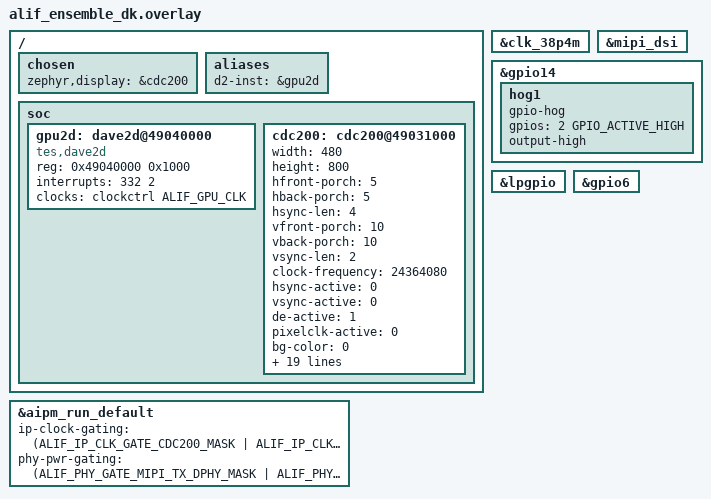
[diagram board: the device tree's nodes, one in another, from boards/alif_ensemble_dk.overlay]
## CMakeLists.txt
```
# Copyright (C) Alif Semiconductor - All Rights Reserved.
# Use, distribution and modification of this code is permitted under the
# terms stated in the Alif Semiconductor Software License Agreement
#
# You should have received a copy of the Alif Semiconductor Software
# License Agreement with this file. If not, please write to:
# contact@alifsemi.com, or visit: https://alifsemi.com/license
#

cmake_minimum_required(VERSION 3.20.0)

find_package(Zephyr REQUIRED HINTS $ENV{ZEPHYR_BASE})
project(lvgl_gui)

# The declarative UI in ui/screen_main.xml is exported to C by
# scripts/gen_ui_xml.py. Generate it into the build tree (never the source
# tree) so read-only-source checkouts and parallel twister builds cannot race
# on a shared file. src/ui_xml.h stays in src/ as the stable interface.
set(ui_xml_c ${CMAKE_CURRENT_BINARY_DIR}/ui_xml.c)

# Application sources: the display bring-up and the exported UI.
target_sources(app PRIVATE
    src/main.c
    ${ui_xml_c}
    src/Alif240_white.c
)

# The generated C includes "ui_xml.h", which lives in src/.
target_include_directories(app PRIVATE src)

# Runs only when the XML or the generator changes.
add_custom_command(
    OUTPUT  ${ui_xml_c}
    COMMAND ${PYTHON_EXECUTABLE}
            ${CMAKE_CURRENT_SOURCE_DIR}/scripts/gen_ui_xml.py
            ${CMAKE_CURRENT_SOURCE_DIR}/ui/screen_main.xml
            ${ui_xml_c}
    DEPENDS ${CMAKE_CURRENT_SOURCE_DIR}/ui/screen_main.xml
            ${CMAKE_CURRENT_SOURCE_DIR}/scripts/gen_ui_xml.py
    COMMENT "Generating ui_xml.c from ui/screen_main.xml"
    VERBATIM
)

# LVGL's upstream D/AVE 2D draw unit includes "bsp_api.h" (LVGL 9.5.0+). The
# include/ directory provides a compatibility shim that maps the TES D/AVE 2D
# driver headers. It must be visible to the LVGL module library build (not just
# the app), so add it to the global include path.
zephyr_include_directories(include)

# The D/AVE 2D draw unit gates its D-cache maintenance (clean/invalidate of the
# GPU source and destination buffers) behind ARM_CORTEX_M55_M85 and
# BSP_CFG_DCACHE_ENABLED. The Alif Cortex-M55 runs with D-cache enabled and the
# GPU buffers live in cacheable SRAM, so this maintenance is required for
# CPU/GPU coherency. Define the macros for the whole build (the LVGL module
# needs them too, not just the app).
zephyr_compile_definitions(ARM_CORTEX_M55_M85=1 BSP_CFG_DCACHE_ENABLED=1)

# The LVGL rendering buffers (.lvgl_buf) and memory pool (.lvgl_heap) are
# rendered into by the D/AVE 2D GPU as a bus master, so relocate them into
# globally addressable SRAM0. In DIRECT mode these full-screen VDBs also serve
# as the CDC200 scan-out framebuffers (zero-copy page-flip).
zephyr_linker_sources_ifdef(CONFIG_LV_Z_VDB_CUSTOM_SECTION
    SECTIONS lvgl_sram.ld)
```

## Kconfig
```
# Copyright (C) Alif Semiconductor - All Rights Reserved.
# Use, distribution and modification of this code is permitted under the
# terms stated in the Alif Semiconductor Software License Agreement
#
# You should have received a copy of the Alif Semiconductor Software
# License Agreement with this file. If not, please write to:
# contact@alifsemi.com, or visit: https://alifsemi.com/license
#

mainmenu "LVGL GUI"

config APP_DAVE2D_HEAP_HWM
	bool "Report the D/AVE 2D heap high-water mark"
	help
	  Fill the D/AVE 2D heap with a known pattern before the heap manager
	  is initialised and periodically log the highest byte that was ever
	  written.

config APP_LVGL_HEAP_STATS
	bool "Report LVGL memory pool and main stack usage"
	select SYS_HEAP_RUNTIME_STATS
	select INIT_STACKS
	select THREAD_STACK_INFO
	help
	  Periodically log the current and peak usage of the LVGL memory pool
	  and the peak usage of the main thread stack.

source "Kconfig.zephyr"
```

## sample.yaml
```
# Copyright (C) Alif Semiconductor - All Rights Reserved.
# Use, distribution and modification of this code is permitted under the
# terms stated in the Alif Semiconductor Software License Agreement
#
# You should have received a copy of the Alif Semiconductor Software
# License Agreement with this file. If not, please write to:
# contact@alifsemi.com, or visit: https://alifsemi.com/license
#

sample:
  name: LVGL XML Widgets
  description: >
    LVGL UI built from a declarative XML description covering the common LVGL
    widgets, exported to C and rendered through the D/AVE 2D GPU on the Alif
    Ensemble E8 DevKit MW405 display.
common:
  modules:
    - lvgl
  tags:
    - display
    - lvgl
    - gui
    - xml
    - dave2d
    - gpu2d
  harness: console
  harness_config:
    type: one_line
    regex:
      - "XML widgets UI created"
  depends_on: display
tests:
  sample.modules.lvgl.gui.dave2d:
    platform_allow:
      - alif_e8_dk/ae822fa0e5597xx0/rtss_he
      - alif_e8_dk/ae822fa0e5597xx0/rtss_hp
    integration_platforms:
      - alif_e8_dk/ae822fa0e5597xx0/rtss_he
```

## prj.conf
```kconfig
# Copyright (C) Alif Semiconductor - All Rights Reserved.
# Use, distribution and modification of this code is permitted under the
# terms stated in the Alif Semiconductor Software License Agreement
#
# You should have received a copy of the Alif Semiconductor Software
# License Agreement with this file. If not, please write to:
# contact@alifsemi.com, or visit: https://alifsemi.com/license
#

# Display pipeline: CDC200 controller + MIPI-DSI host + MW405 panel.
CONFIG_DISPLAY=y
CONFIG_MIPI_DSI=y

# LVGL core.
CONFIG_LVGL=y

# Widgets used by the exported UI (ui/screen_main.xml -> src/ui_xml.c). Most
# default to y in the LVGL Kconfig; set them explicitly so the sample is
# self-contained and does not silently drop a widget if a default changes.
CONFIG_LV_USE_LABEL=y
CONFIG_LV_USE_BUTTON=y
CONFIG_LV_USE_SLIDER=y
CONFIG_LV_USE_BAR=y
CONFIG_LV_USE_SWITCH=y
CONFIG_LV_USE_CHECKBOX=y
CONFIG_LV_USE_ARC=y
CONFIG_LV_USE_LED=y
CONFIG_LV_USE_LINE=y
CONFIG_LV_USE_IMAGE=y

# Fonts used by the UI (montserrat_14 is the default font; 24 is used for the
# title label).
CONFIG_LV_FONT_MONTSERRAT_14=y
CONFIG_LV_FONT_MONTSERRAT_24=y

# Flexbox layout used by the root container in the exported UI.
CONFIG_LV_USE_FLEX=y

# Refresh at ~60 FPS (LVGL default is 33 ms / ~30 FPS).
CONFIG_LV_DEF_REFR_PERIOD=16

# LVGL memory pool. Every lv_malloc() comes from here: widget objects, the
# simple-layer scratch buffers and the transient glyph bitmaps lv_draw_label
# allocates per letter. The UI peaks at about 11 KB; 64 KB leaves room for
# UI changes. It lives in .lvgl_heap (SRAM0). The pool is a sys_heap that
# defaults to SYS_HEAP_SMALL_ONLY (DTCM is 256 KB), which supports at most
# 262136 bytes; set CONFIG_SYS_HEAP_AUTO=y if the pool is made larger.
CONFIG_LV_Z_MEM_POOL_SIZE=65536
CONFIG_LV_DRAW_LAYER_SIMPLE_BUF_SIZE=49152

# Double-buffered, statically allocated rendering buffers. The custom sections
# (.lvgl_buf / .lvgl_heap) are relocated to globally-addressable SRAM0 by
# lvgl_sram.ld so the D/AVE 2D GPU can render into them and the VDBs can also
# serve as the CDC200 scan-out framebuffers (DIRECT mode zero-copy page-flip).
CONFIG_LV_Z_BUFFER_ALLOC_STATIC=y
CONFIG_LV_Z_DOUBLE_VDB=y
CONFIG_LV_Z_VDB_CUSTOM_SECTION=y
CONFIG_LV_Z_MEMORY_POOL_CUSTOM_SECTION=y

# Size the VDBs for the RGB565 panel (16 bpp). The Zephyr LVGL Kconfig has an
# unconditional "default 32" before the "default 16 if LV_COLOR_DEPTH_16"
# entry, so pin the bits-per-pixel explicitly.
CONFIG_LV_Z_BITS_PER_PIXEL=16

# DIRECT-mode rendering: two full-screen VDBs in SRAM0 ARE the scan-out
# framebuffers. main.c page-flips via cdc200_swap_fb() at vsync.
CONFIG_LV_Z_VDB_SIZE=100

# Offload LVGL rendering to the D/AVE 2D GPU.
CONFIG_DAVE2D=y
CONFIG_LV_USE_DRAW_DAVE2D=y

# Use the Cortex-M55 Helium (MVE) software-render backend for the operations the
# D/AVE 2D unit cannot offload, instead of scalar C.
CONFIG_LV_DRAW_SW_ASM_HELIUM=y

# Build for speed (-O2). There is ample MRAM headroom for the larger code.
CONFIG_SPEED_OPTIMIZATIONS=y

# 16-bit colour depth to match the RGB565 panel.
CONFIG_LV_COLOR_DEPTH_16=y

CONFIG_MAIN_STACK_SIZE=8192

CONFIG_LOG=y
```

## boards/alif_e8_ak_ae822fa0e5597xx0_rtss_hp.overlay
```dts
/* Copyright (C) Alif Semiconductor - All Rights Reserved.
 * Use, distribution and modification of this code is permitted under the
 * terms stated in the Alif Semiconductor Software License Agreement
 *
 * You should have received a copy of the Alif Semiconductor Software
 * License Agreement with this file. If not, please write to:
 * contact@alifsemi.com, or visit: https://alifsemi.com/license
 *
 */
#include "alif_ensemble_dk.overlay"
```

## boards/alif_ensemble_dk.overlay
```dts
/* Copyright (C) Alif Semiconductor - All Rights Reserved.
 * Use, distribution and modification of this code is permitted under the
 * terms stated in the Alif Semiconductor Software License Agreement
 *
 * You should have received a copy of the Alif Semiconductor Software
 * License Agreement with this file. If not, please write to:
 * contact@alifsemi.com, or visit: https://alifsemi.com/license
 *
 */

#include <zephyr/dt-bindings/clock/alif_ensemble_clocks.h>
#include <dt-bindings/misc/alif_aipm_ensemble_gen2.h>

/ {
	chosen {
		zephyr,display = &cdc200;
	};

	aliases {
		/* Used by the D/AVE 2D (d1) layer to locate the GPU node. */
		d2-inst = &gpu2d;
	};

	soc {
		gpu2d: dave2d@49040000 {
			compatible = "tes,dave2d";
			reg = <0x49040000 0x1000>;
			interrupts = <332 2>;
			clocks = <&clockctrl ALIF_GPU_CLK>;
		};

		/* Override the placeholder CDC200 timings for the 480x800 MW405 panel. */
		cdc200: cdc200@49031000 {
			width = <480>;
			height = <800>;
			hfront-porch = <5>;
			hback-porch = <5>;
			hsync-len = <4>;
			vfront-porch = <10>;
			vback-porch = <10>;
			vsync-len = <2>;
			clock-frequency = <24364080>;
			hsync-active = <0>;
			vsync-active = <0>;
			de-active = <1>;
			pixelclk-active = <0>;
			bg-color = <0>;
			enable-l1 = <1>;
			pixel-fmt-l1 = "rgb-565";
			def-back-color-l1 = <0>;
			win-x0-l1 = <0>;
			win-y0-l1 = <0>;
			win-x1-l1 = <480>;
			win-y1-l1 = <800>;
			blend-factor1-l1 = <4>;
			blend-factor2-l1 = <5>;
			const-alpha-l1 = <0xff>;
			enable-l2 = <0>;
			pixel-fmt-l2 = "undefined";
			win-x0-l2 = <0>;
			win-y0-l2 = <0>;
			win-x1-l2 = <0>;
			win-y1-l2 = <0>;
			blend-factor1-l2 = <6>;
			blend-factor2-l2 = <7>;
			const-alpha-l2 = <0xff>;
		};
	};
};

&aipm_run_default {
	ip-clock-gating = <(ALIF_IP_CLK_GATE_CDC200_MASK |
			    ALIF_IP_CLK_GATE_MIPI_DSI_MASK |
			    ALIF_IP_CLK_GATE_GPU_MASK)>;
	phy-pwr-gating  = <(ALIF_PHY_GATE_MIPI_TX_DPHY_MASK |
			    ALIF_PHY_GATE_MIPI_RX_DPHY_MASK |
			    ALIF_PHY_GATE_MIPI_PLL_DPHY_MASK |
			    ALIF_PHY_GATE_LDO_MASK)>;
};

&clk_38p4m {
	status = "okay";
};

&mipi_dsi {
	status = "okay";
};

/* GPIO controller for the MIPI camera/display mux (cam-disp-mux-gpios on the DSI
 * host). The application drives it to route the MIPI lanes to the panel.
 */
&gpio14 {
	status = "okay";

	hog1 {
		gpio-hog;
		gpios = <2 GPIO_ACTIVE_HIGH>;
		output-high;
	};
};

/* GPIO controllers used by the MW405 panel (reset on lpgpio, backlight on gpio6). */
&lpgpio {
	status = "okay";
};

&gpio6 {
	status = "okay";
};
```

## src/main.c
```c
/* Copyright (C) Alif Semiconductor - All Rights Reserved.
 * Use, distribution and modification of this code is permitted under the
 * terms stated in the Alif Semiconductor Software License Agreement
 *
 * You should have received a copy of the Alif Semiconductor Software
 * License Agreement with this file. If not, please write to:
 * contact@alifsemi.com, or visit: https://alifsemi.com/license
 *
 */

#include <zephyr/kernel.h>
#include <zephyr/init.h>
#include <zephyr/device.h>
#include <zephyr/drivers/display.h>
#include <zephyr/drivers/display/cdc200.h>
#if defined(CONFIG_MIPI_DSI)
#include <zephyr/drivers/mipi_dsi/dsi_dw.h>
#endif
#include <zephyr/cache.h>
#include <zephyr/linker/section_tags.h>
#include <zephyr/logging/log.h>

#include <lvgl.h>

#include <dave_d0lib.h>

#include "ui_xml.h"

#if defined(CONFIG_APP_LVGL_HEAP_STATS)
#include <lvgl_mem.h>
#endif

LOG_MODULE_REGISTER(app, CONFIG_LOG_DEFAULT_LEVEL);

#if DT_NODE_HAS_STATUS(DT_ALIAS(panel), okay)
static int panel_power_on(void)
{
	const struct device *panel_dev = DEVICE_DT_GET(DT_ALIAS(panel));
	int ret;

	if (!device_is_ready(panel_dev)) {
		LOG_ERR("Display panel device not ready");
		return -ENODEV;
	}

	ret = display_blanking_off(panel_dev);
	if (ret) {
		LOG_ERR("Failed to turn display panel on (%d)", ret);
	}

	return ret;
}
#endif

/*
 * D/AVE 2D working memory (display lists, render buffers, ...). The LVGL D/AVE 2D
 * draw unit allocates from this heap inside lv_draw_dave2d_init(), which runs as
 * part of lv_init(). Zephyr's LVGL glue calls lv_init() automatically from a
 * SYS_INIT() hook at the APPLICATION init level, so the heap must already be
 * initialised by then - hence the POST_KERNEL SYS_INIT() below, which always
 * runs before any APPLICATION-level hook. The heap lives in SRAM1; the LVGL
 * rendering buffers + memory pool live in SRAM0 (see lvgl_sram.ld) - both
 * globally addressable so the GPU can reach them.
 */
#define DAVE2D_HEAP_SIZE (64 * 1024)
static uint8_t __alif_sram1_section
	__aligned(CONFIG_D0_FIXED_RANGE_ALIGNMENT) dave2d_heap[DAVE2D_HEAP_SIZE];

#if defined(CONFIG_APP_DAVE2D_HEAP_HWM)
/*
 * The D/AVE 2D fixed-range allocator is first-fit from the bottom of the heap
 * and writes a block header right after every allocation it splits off, so the
 * highest byte that no longer holds the fill pattern marks the peak extent.
 */
#define DAVE2D_HEAP_FILL 0xA5A5A5A5U

static uint32_t dave2d_heap_hwm(void)
{
	const uint32_t *words = (const uint32_t *)dave2d_heap;
	size_t i = DAVE2D_HEAP_SIZE / sizeof(uint32_t);

	while (i > 0 && words[i - 1] == DAVE2D_HEAP_FILL) {
		i--;
	}

	return i * sizeof(uint32_t);
}
#endif

#if defined(CONFIG_APP_DAVE2D_HEAP_HWM) || defined(CONFIG_APP_LVGL_HEAP_STATS)
#define MEM_REPORT_INTERVAL_MS 10000

static void mem_report(void)
{
#if defined(CONFIG_APP_DAVE2D_HEAP_HWM)
	uint32_t hwm = dave2d_heap_hwm();

	LOG_INF("D/AVE 2D heap high-water mark: %u of %u bytes (%u%%)", (unsigned int)hwm,
		(unsigned int)DAVE2D_HEAP_SIZE, (unsigned int)((hwm * 100U) / DAVE2D_HEAP_SIZE));
#endif
#if defined(CONFIG_APP_LVGL_HEAP_STATS)
	struct sys_memory_stats stats;
	size_t stack_size = k_current_get()->stack_info.size;
	size_t stack_unused = 0;

	lvgl_heap_stats(&stats);
	(void)k_thread_stack_space_get(k_current_get(), &stack_unused);

	LOG_INF("LVGL pool: %u allocated, %u peak of %u bytes (peak %u%%)",
		(unsigned int)stats.allocated_bytes, (unsigned int)stats.max_allocated_bytes,
		(unsigned int)CONFIG_LV_Z_MEM_POOL_SIZE,
		(unsigned int)((stats.max_allocated_bytes * 100U) / CONFIG_LV_Z_MEM_POOL_SIZE));
	LOG_INF("Main stack: %u peak of %u bytes (%u%%)", (unsigned int)(stack_size - stack_unused),
		(unsigned int)stack_size,
		(unsigned int)(((stack_size - stack_unused) * 100U) / stack_size));
#endif
}
#endif

static int dave2d_heap_init(void)
{
#if defined(CONFIG_APP_DAVE2D_HEAP_HWM)
	for (size_t i = 0; i < DAVE2D_HEAP_SIZE / sizeof(uint32_t); i++) {
		((uint32_t *)dave2d_heap)[i] = DAVE2D_HEAP_FILL;
	}
#endif

	if (!d0_initheapmanager(dave2d_heap, sizeof(dave2d_heap), d0_mm_fixed_range,
				NULL, 0, 0, 0, d0_ma_unified)) {
		LOG_ERR("Failed to initialise the D/AVE 2D heap manager");
		return -ENOMEM;
	}

	return 0;
}
SYS_INIT(dave2d_heap_init, POST_KERNEL, CONFIG_KERNEL_INIT_PRIORITY_DEFAULT);

/*
 * DIRECT-mode flush callback with vsync synchronization. In DIRECT mode the
 * two full-screen LVGL VDBs ARE the scan-out framebuffers (both in SRAM0). The
 * GPU renders directly into the back buffer, and this callback page-flips via
 * cdc200_swap_fb() then waits for the CDC200 LINE IRQ so LVGL never touches the
 * new back buffer until the old front is released (no tearing).
 */
static void direct_flush_cb(lv_display_t *disp, const lv_area_t *area,
			     uint8_t *px_map)
{
	const struct device *dev = lv_display_get_user_data(disp);

	if (lv_display_flush_is_last(disp)) {
		uint32_t h = lv_display_get_vertical_resolution(disp);
		uint32_t w = lv_display_get_horizontal_resolution(disp);
		uint32_t stride = w * (LV_COLOR_DEPTH / 8);

		sys_cache_data_flush_range(px_map, stride * h);

		struct cdc200_fb_desc fb = {
			.fb_addr = px_map,
			.fb_size = stride * h,
		};
		int ret;

		cdc200_swap_fb(dev, 0, &fb);
		ret = cdc200_wait_vsync(dev, K_MSEC(50));
		if (ret) {
			LOG_ERR("Timed out waiting for CDC200 vblank (%d)", ret);
		}
	}

	lv_display_flush_ready(disp);
}

/*
 * Override the LVGL glue's default PARTIAL mode with a zero-copy DIRECT-mode
 * page-flip. The CDC200 is pointed at one of the VDBs initially so it has a
 * valid scan-out address before LVGL renders its first frame.
 */
static void setup_direct_mode(const struct device *display_dev, lv_display_t *disp)
{
	lv_display_set_render_mode(disp, LV_DISPLAY_RENDER_MODE_DIRECT);
	lv_display_set_flush_cb(disp, direct_flush_cb);
	lv_display_set_user_data(disp, (void *)display_dev);

	lv_draw_buf_t *buf0 = lv_display_get_buf_active(disp);

	if (buf0) {
		uint32_t h = lv_display_get_vertical_resolution(disp);
		uint32_t w = lv_display_get_horizontal_resolution(disp);
		struct cdc200_fb_desc fb = {
			.fb_addr = buf0->data,
			.fb_size = w * (LV_COLOR_DEPTH / 8) * h,
		};

		cdc200_swap_fb(display_dev, 0, &fb);
	}
}

int main(void)
{
	const struct device *display_dev = DEVICE_DT_GET(DT_CHOSEN(zephyr_display));

	if (!device_is_ready(display_dev)) {
		LOG_ERR("Display device not ready");
		return 0;
	}

#if defined(CONFIG_MIPI_DSI)
	{
		const struct device *dsi = DEVICE_DT_GET(DT_NODELABEL(mipi_dsi));
		int ret;

		if (!device_is_ready(dsi)) {
			LOG_ERR("MIPI-DSI host not ready");
			return 0;
		}

		/*
		 * The panel is initialised over the DSI link in command mode.
		 * Switch the host to video mode so the CDC200 framebuffer is
		 * actually streamed to the panel; without this the screen stays
		 * black even though the panel configured successfully.
		 */
		ret = dsi_dw_set_mode(dsi, DSI_DW_VIDEO_MODE);
		if (ret) {
			LOG_ERR("Failed to set DSI video mode (%d)", ret);
			return 0;
		}
	}
#endif

#if DT_NODE_HAS_STATUS(DT_ALIAS(panel), okay)
	if (panel_power_on()) {
		return 0;
	}
#endif

	/*
	 * The CDC200 scan-out engine is not started by its own driver init, and
	 * the generic display_blanking_off() API the LVGL glue calls is a no-op
	 * for it. Start it explicitly here, or the panel stays dark.
	 */
	cdc200_set_enable(display_dev, true);

	lv_display_t *disp = lv_display_get_default();

	setup_direct_mode(display_dev, disp);

	/* Build the UI described by ui/screen_main.xml (exported to ui_xml.c). */
	ui_xml_create(lv_screen_active());

	LOG_INF("XML widgets UI created");

#if defined(CONFIG_APP_DAVE2D_HEAP_HWM) || defined(CONFIG_APP_LVGL_HEAP_STATS)
	int64_t next_report = k_uptime_get() + MEM_REPORT_INTERVAL_MS;
#endif

	while (1) {
		uint32_t sleep_ms = lv_timer_handler();

#if defined(CONFIG_APP_DAVE2D_HEAP_HWM) || defined(CONFIG_APP_LVGL_HEAP_STATS)
		int64_t now = k_uptime_get();

		if (now >= next_report) {
			mem_report();
			next_report = now + MEM_REPORT_INTERVAL_MS;
		}
		/* LVGL pauses its refresh timer while the screen is unchanged. */
		sleep_ms = MIN(sleep_ms, (uint32_t)(next_report - now));
#endif

		k_msleep(MIN(sleep_ms, INT32_MAX));
	}

	return 0;
}
```

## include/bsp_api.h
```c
/* Copyright (C) Alif Semiconductor - All Rights Reserved.
 * Use, distribution and modification of this code is permitted under the
 * terms stated in the Alif Semiconductor Software License Agreement
 *
 * You should have received a copy of the Alif Semiconductor Software
 * License Agreement with this file. If not, please write to:
 * contact@alifsemi.com, or visit: https://alifsemi.com/license
 *
 */

#ifndef BSP_API_H
#define BSP_API_H

/*
 * Compatibility shim for LVGL's D/AVE 2D draw unit (LVGL 9.5.0+).
 *
 * Since v9.5.0 the upstream D/AVE 2D draw unit header (lv_draw_dave2d.h)
 * includes "bsp_api.h" - the FSP BSP umbrella header - instead of
 * "hal_data.h". On the FSP that header transitively provides CMSIS, the
 * generated display-geometry macros (DISPLAY_*_INPUT0) and the framebuffer
 * colour-format helper lv_draw_dave2d_cf_fb_get(). Alif has no FSP, so this
 * shim supplies the small subset the draw unit actually uses.
 *
 * The draw unit's D-cache maintenance runs under ARM_CORTEX_M55_M85 (defined by
 * this sample's CMakeLists.txt), so it uses portable CMSIS SCB_* helpers and the
 * Alif d1_cacheblockflush() helper - both provided by the headers below.
 */

#include <cmsis_core.h>   /* SCB_CleanInvalidateDCache_by_Addr() on the M55 */
#include <dave_driver.h>  /* d2_* types used by lv_draw_dave2d_cf_fb_get() */
#include <dave_d0lib.h>   /* d1_cacheblockflush() */

/*
 * D/AVE 2D render-target geometry. In DIRECT mode the LVGL VDBs are full-screen
 * framebuffers, so this matches the 480x800 MW405 panel configured for the
 * CDC200 controller in the board overlay (keep in sync with cdc200 width/height).
 */
#define DISPLAY_HSIZE_INPUT0                480
#define DISPLAY_VSIZE_INPUT0                800
#define DISPLAY_BUFFER_STRIDE_PIXELS_INPUT0 480

/*
 * D/AVE 2D framebuffer colour format. On Alif the LVGL framebuffer always
 * matches the configured LVGL colour depth.
 */
static inline d2_s32 lv_draw_dave2d_cf_fb_get(void)
{
#if defined(LV_COLOR_DEPTH) && LV_COLOR_DEPTH == 32
	return d2_mode_argb8888;
#else
	return d2_mode_rgb565;
#endif
}

#endif /* BSP_API_H */
```

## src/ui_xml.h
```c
/* Copyright (C) Alif Semiconductor - All Rights Reserved.
 * Use, distribution and modification of this code is permitted under the
 * terms stated in the Alif Semiconductor Software License Agreement
 *
 * You should have received a copy of the Alif Semiconductor Software
 * License Agreement with this file. If not, please write to:
 * contact@alifsemi.com, or visit: https://alifsemi.com/license
 *
 */

#ifndef UI_XML_H
#define UI_XML_H

#include <lvgl.h>

#ifdef __cplusplus
extern "C" {
#endif

/*
 * Build the UI described by ui/screen_main.xml on the given parent.
 *
 * This is the generated C equivalent of the declarative XML: the Alif LVGL
 * fork has no runtime XML loader (lv_xml_*), so scripts/gen_ui_xml.py compiles
 * the XML offline into this function. Every widget here maps 1:1 to a tag in
 * screen_main.xml.
 */
void ui_xml_create(lv_obj_t *parent);

#ifdef __cplusplus
}
#endif

#endif /* UI_XML_H */
```
